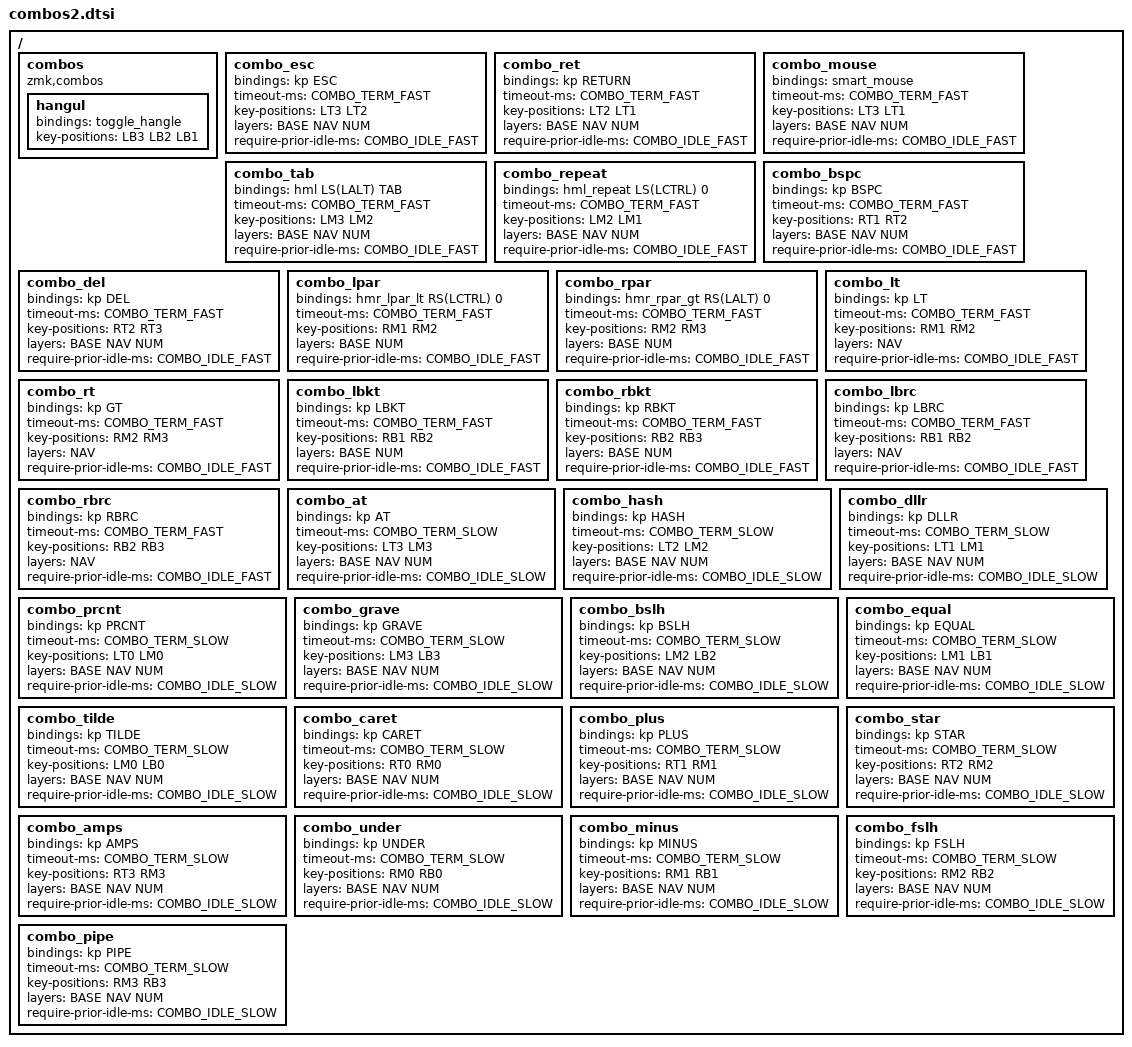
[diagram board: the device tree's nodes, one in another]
#define COMBO_TERM_FAST 18
#define COMBO_TERM_SLOW 30

#define COMBO_IDLE_FAST 150
#define COMBO_IDLE_SLOW 50
/ {
    combos {
        compatible = "zmk,combos";
        hangul {
            bindings = <&toggle_hangle>;
            key-positions = <LB3 LB2 LB1>;
        };
    };
            // toggle_colemac_qwert {
        //     bindings = <&tog 1>;
        //     key-positions = <RB2 RB3>;
        // };
        /* Horizontal combos - left hand */

        combo_esc {
            bindings = <&kp ESC>;
            timeout-ms = <COMBO_TERM_FAST>;
            key-positions = <LT3 LT2>;
            layers = <BASE NAV NUM>;
            require-prior-idle-ms = <COMBO_IDLE_FAST>;
        };

        combo_ret {
            bindings = <&kp RETURN>;
            timeout-ms = <COMBO_TERM_FAST>;
            key-positions = <LT2 LT1>;
            layers = <BASE NAV NUM>;
            require-prior-idle-ms = <COMBO_IDLE_FAST>;
        };


        combo_mouse {
            bindings = <&smart_mouse>;
            timeout-ms = <COMBO_TERM_FAST>;
            key-positions = <LT3 LT1>;
            layers = <BASE NAV NUM>;
            require-prior-idle-ms = <COMBO_IDLE_FAST>;
        };

        // make homerow combos tap-only (so HRMs can be chorded instantaneously)

        combo_tab {
            bindings = <&hml LS(LALT) TAB>;
            timeout-ms = <COMBO_TERM_FAST>;
            key-positions = <LM3 LM2>;
            layers = <BASE NAV NUM>;
            require-prior-idle-ms = <COMBO_IDLE_FAST>;
        };

        combo_repeat {
            bindings = <&hml_repeat LS(LCTRL) 0>;
            timeout-ms = <COMBO_TERM_FAST>;
            key-positions = <LM2 LM1>;
            layers = <BASE NAV NUM>;
            require-prior-idle-ms = <COMBO_IDLE_FAST>;
        };

        /* Horizontal combos - right hand */
        combo_bspc {
            bindings = <&kp BSPC>;
            timeout-ms = <COMBO_TERM_FAST>;
            key-positions = <RT1 RT2>;
            layers = <BASE NAV NUM>;
            require-prior-idle-ms = <COMBO_IDLE_FAST>;
        };

        combo_del {
            bindings = <&kp DEL>;
            timeout-ms = <COMBO_TERM_FAST>;
            key-positions = <RT2 RT3>;
            layers = <BASE NAV NUM>;
            require-prior-idle-ms = <COMBO_IDLE_FAST>;
        };



        combo_lpar {
            bindings = <&hmr_lpar_lt RS(LCTRL) 0>;
            timeout-ms = <COMBO_TERM_FAST>;
            key-positions = <RM1 RM2>;
            layers = <BASE NUM>;
            require-prior-idle-ms = <COMBO_IDLE_FAST>;
        };

        combo_rpar {
            bindings = <&hmr_rpar_gt RS(LALT) 0>;
            timeout-ms = <COMBO_TERM_FAST>;
            key-positions = <RM2 RM3>;
            layers = <BASE NUM>;
            require-prior-idle-ms = <COMBO_IDLE_FAST>;
        };

        combo_lt {
            bindings = <&kp LT>;
            timeout-ms = <COMBO_TERM_FAST>;
            key-positions = <RM1 RM2>;
            layers = <NAV>;
            require-prior-idle-ms = <COMBO_IDLE_FAST>;
        };

        combo_rt {
            bindings = <&kp GT>;
            timeout-ms = <COMBO_TERM_FAST>;
            key-positions = <RM2 RM3>;
            layers = <NAV>;
            require-prior-idle-ms = <COMBO_IDLE_FAST>;
        };

        combo_lbkt {
            bindings = <&kp LBKT>;
            timeout-ms = <COMBO_TERM_FAST>;
            key-positions = <RB1 RB2>;
            layers = <BASE NUM>;
            require-prior-idle-ms = <COMBO_IDLE_FAST>;
        };

        combo_rbkt {
            bindings = <&kp RBKT>;
            timeout-ms = <COMBO_TERM_FAST>;
            key-positions = <RB2 RB3>;
            layers = <BASE NUM>;
            require-prior-idle-ms = <COMBO_IDLE_FAST>;
        };

        combo_lbrc {
            bindings = <&kp LBRC>;
            timeout-ms = <COMBO_TERM_FAST>;
            key-positions = <RB1 RB2>;
            layers = <NAV>;
            require-prior-idle-ms = <COMBO_IDLE_FAST>;
        };

        combo_rbrc {
            bindings = <&kp RBRC>;
            timeout-ms = <COMBO_TERM_FAST>;
            key-positions = <RB2 RB3>;
            layers = <NAV>;
            require-prior-idle-ms = <COMBO_IDLE_FAST>;
        };

        /* Vertical combos - left hand */
        combo_at {
            bindings = <&kp AT>;
            timeout-ms = <COMBO_TERM_SLOW>;
            key-positions = <LT3 LM3>;
            layers = <BASE NAV NUM>;
            require-prior-idle-ms = <COMBO_IDLE_SLOW>;
        };

        combo_hash {
            bindings = <&kp HASH>;
            timeout-ms = <COMBO_TERM_SLOW>;
            key-positions = <LT2 LM2>;
            layers = <BASE NAV NUM>;
            require-prior-idle-ms = <COMBO_IDLE_SLOW>;
        };

        combo_dllr {
            bindings = <&kp DLLR>;
            timeout-ms = <COMBO_TERM_SLOW>;
            key-positions = <LT1 LM1>;
            layers = <BASE NAV NUM>;
            require-prior-idle-ms = <COMBO_IDLE_SLOW>;
        };

        combo_prcnt {
            bindings = <&kp PRCNT>;
            timeout-ms = <COMBO_TERM_SLOW>;
            key-positions = <LT0 LM0>;
            layers = <BASE NAV NUM>;
            require-prior-idle-ms = <COMBO_IDLE_SLOW>;
        };

        combo_grave {
            bindings = <&kp GRAVE>;
            timeout-ms = <COMBO_TERM_SLOW>;
            key-positions = <LM3 LB3>;
            layers = <BASE NAV NUM>;
            require-prior-idle-ms = <COMBO_IDLE_SLOW>;
        };

        combo_bslh {
            bindings = <&kp BSLH>;
            timeout-ms = <COMBO_TERM_SLOW>;
            key-positions = <LM2 LB2>;
            layers = <BASE NAV NUM>;
            require-prior-idle-ms = <COMBO_IDLE_SLOW>;
        };

        combo_equal {
            bindings = <&kp EQUAL>;
            timeout-ms = <COMBO_TERM_SLOW>;
            key-positions = <LM1 LB1>;
            layers = <BASE NAV NUM>;
            require-prior-idle-ms = <COMBO_IDLE_SLOW>;
        };

        combo_tilde {
            bindings = <&kp TILDE>;
            timeout-ms = <COMBO_TERM_SLOW>;
            key-positions = <LM0 LB0>;
            layers = <BASE NAV NUM>;
            require-prior-idle-ms = <COMBO_IDLE_SLOW>;
        };

        /* Vertical combos - right hand */
        combo_caret {
            bindings = <&kp CARET>;
            timeout-ms = <COMBO_TERM_SLOW>;
            key-positions = <RT0 RM0>;
            layers = <BASE NAV NUM>;
            require-prior-idle-ms = <COMBO_IDLE_SLOW>;
        };

        combo_plus {
            bindings = <&kp PLUS>;
            timeout-ms = <COMBO_TERM_SLOW>;
            key-positions = <RT1 RM1>;
            layers = <BASE NAV NUM>;
            require-prior-idle-ms = <COMBO_IDLE_SLOW>;
        };

        combo_star {
            bindings = <&kp STAR>;
            timeout-ms = <COMBO_TERM_SLOW>;
            key-positions = <RT2 RM2>;
            layers = <BASE NAV NUM>;
            require-prior-idle-ms = <COMBO_IDLE_SLOW>;
        };

        combo_amps {
            bindings = <&kp AMPS>;
            timeout-ms = <COMBO_TERM_SLOW>;
            key-positions = <RT3 RM3>;
            layers = <BASE NAV NUM>;
            require-prior-idle-ms = <COMBO_IDLE_SLOW>;
        };

        combo_under {
            bindings = <&kp UNDER>;
            timeout-ms = <COMBO_TERM_SLOW>;
            key-positions = <RM0 RB0>;
            layers = <BASE NAV NUM>;
            require-prior-idle-ms = <COMBO_IDLE_SLOW>;
        };

        combo_minus {
            bindings = <&kp MINUS>;
            timeout-ms = <COMBO_TERM_SLOW>;
            key-positions = <RM1 RB1>;
            layers = <BASE NAV NUM>;
            require-prior-idle-ms = <COMBO_IDLE_SLOW>;
        };

        combo_fslh {
            bindings = <&kp FSLH>;
            timeout-ms = <COMBO_TERM_SLOW>;
            key-positions = <RM2 RB2>;
            layers = <BASE NAV NUM>;
            require-prior-idle-ms = <COMBO_IDLE_SLOW>;
        };

        combo_pipe {
            bindings = <&kp PIPE>;
            timeout-ms = <COMBO_TERM_SLOW>;
            key-positions = <RM3 RB3>;
            layers = <BASE NAV NUM>;
            require-prior-idle-ms = <COMBO_IDLE_SLOW>;
        };

};
